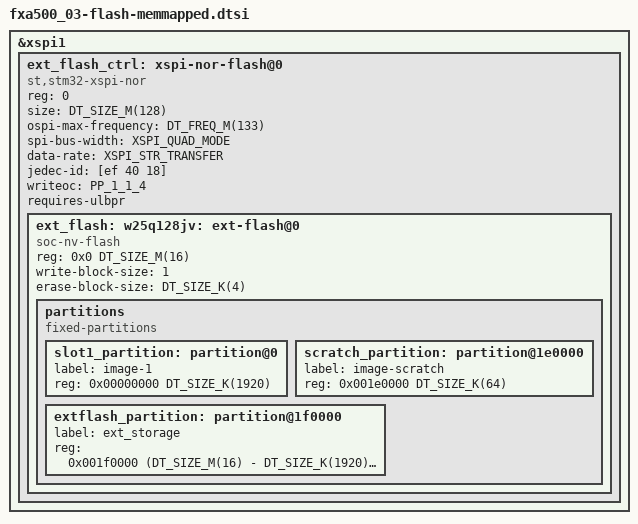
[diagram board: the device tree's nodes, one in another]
/* Declare external Flash as memory-mapped */
&xspi1 {

    ext_flash_ctrl: xspi-nor-flash@0 {
		status = "okay";
		compatible = "st,stm32-xspi-nor";
		reg = <0>;
		size = <DT_SIZE_M(128)>;  /* 128 Mbits */
		ospi-max-frequency = <DT_FREQ_M(133)>;
		spi-bus-width = <XSPI_QUAD_MODE>;
		// Схоже шо XSPI_DTR_TRANSFER можливий лише у XSPI_OCTO_MODE
		data-rate = <XSPI_STR_TRANSFER>;
		// four-byte-opcodes;
		jedec-id = [ef 40 18];
		writeoc = "PP_1_1_4";
		requires-ulbpr;

		#address-cells = <1>;
		#size-cells = <1>;
		ranges = <0x0 0x90000000 DT_SIZE_M(16)>; /* Ext Flash mem-mapped to 0x90000000 */

		ext_flash: w25q128jv: ext-flash@0 {
			compatible = "soc-nv-flash";
			status = "okay";
			reg = <0x0 DT_SIZE_M(16)>;
			write-block-size = <1>;
			erase-block-size = <DT_SIZE_K(4)>;

			partitions {
				compatible = "fixed-partitions";
				#address-cells = <1>;
				#size-cells = <1>;

				// Нам треба slot1 розміром як slot0
				slot1_partition: partition@0 {
					label = "image-1";
					reg = <0x00000000 DT_SIZE_K(1920)>;
				};

				// У нас різні розміри сторінок. У процесора 8КБайт, а у памʼяті - 4КБайт.
				// Тому нам підійде BOOT_SWAP_USING_SCRATCH ну або BOOT_UPGRADE_ONLY
				// Для цього треба розділ scratch_partition
				// Мікросхема W25Q128JV має декілька команд на стирання
				// Немає впевненості шо драйвер їх автоматично застосує.
				// Можна буде глянути через CONFIG_FLASH_LOG_LEVEL_DBG=y
				// - Стирання сектора 4КB - 20h
				// - Стирання блоку 32KB - 52h
				// - Стирання блоку 64KB - D8h

				scratch_partition: partition@1e0000 {
					label = "image-scratch";
					// reg = <0x001e0000 DT_SIZE_K(1920)>; /* Можливо не треба його робити як прошивка, достатньо 8KB або 16 */
					reg = <0x001e0000 DT_SIZE_K(64)>;
				};

				// Все інше виділяємо під extflash_partition
				// extflash_partition: partition@3c0000 {  /* Якшо scratch_partition 1920КБ */
				extflash_partition: partition@1f0000 { /* Якшо scratch_partition 64КБ */
					label = "ext_storage";
					// reg = <0x003c0000 (DT_SIZE_M(16) - DT_SIZE_K(1920) - DT_SIZE_K(1920))>;
					reg = <0x001f0000 (DT_SIZE_M(16) - DT_SIZE_K(1920) - DT_SIZE_K(64))>;
				};
			};

			// partitions {
			// 	compatible = "fixed-partitions";
			// 	#address-cells = <1>;
			// 	#size-cells = <1>;

			// 	extflash_partition: partition@0 {
			// 		// label = "storage";
			// 		// label = "nor";
			// 		label = "ext_storage";
			// 		reg = <0x00000000 DT_SIZE_M(16)>;
			// 	};
			// };
		};
	};
};

